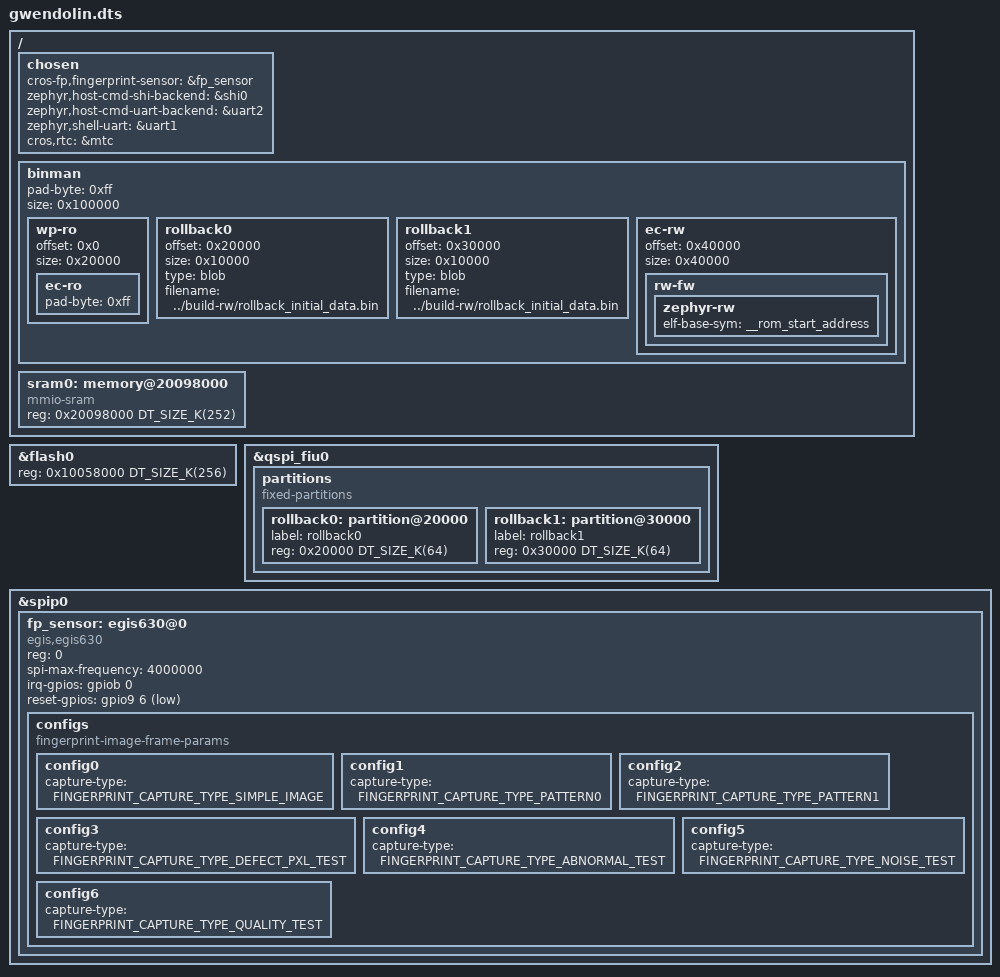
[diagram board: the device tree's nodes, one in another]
/* Copyright 2025 The ChromiumOS Authors.
 * Use of this source code is governed by a BSD-style license that can be
 * found in the LICENSE file.
 */

#include "gpio.dtsi"
#include "gwendolin/rwsig.dtsi"
#include "soc.dtsi"

#include <cros/integrated_fwid.dtsi>

#define EGIG630_DEFAULT_IMAGE_PROPS \
	width = <80>; \
	height = <64>; \
	bits-per-pixel = <8>; \
	frame-size = <5120>; \
	v4l2-pixel-format = "V4L2_PIX_FMT_GREY";

#define EGIG630_TEST_IMAGE_PROPS \
	width = <80>; \
	height = <64>; \
	bits-per-pixel = <16>; \
	frame-size = <10240>; \
	v4l2-pixel-format = "V4L2_PIX_FMT_GREY";

/ {
	chosen {
		cros-fp,fingerprint-sensor = &fp_sensor;
		zephyr,host-cmd-shi-backend = &shi0;
		zephyr,host-cmd-uart-backend = &uart2;
		zephyr,shell-uart = &uart1;
		cros,rtc = &mtc;
	};

	binman {
		pad-byte = <0xff>;

		/* Total Flash size is 1 MB. */
		size = <0x100000>;

		/* First 128 kB (uniform 4 kB sectors) used for RO */
		wp-ro {
			offset = <0x0>;
			size = <0x20000>;
			ec-ro {
				pad-byte = <0xff>;
			};
		};

		/* Two rollback sections (64 kB each) */
		rollback0 {
			offset = <0x20000>;
			size = <0x10000>;
			type = "blob";
			filename = "../build-rw/rollback_initial_data.bin";
		};

		rollback1 {
			offset = <0x30000>;
			size = <0x10000>;
			type = "blob";
			filename = "../build-rw/rollback_initial_data.bin";
		};

		/* 256 kB used for RW - gwendolin ECOS flash size */
		ec-rw {
			offset = <0x40000>;
			size = <0x40000>;
			rw-fw {
				/*
				 * Clang doesn't emit STT_SECTION symbols (also
				 * called 'section symbols'), so 'rom_start'
				 * symbol is not available. Fortunately, Zephyr
				 * linker scripts provide '__rom_start_address'
				 * symbol which points to the beginning of
				 * 'rom_start' section.
				 */
				zephyr-rw {
					elf-base-sym = "__rom_start_address";
				};
			};
		};
	};
};

/*
 *           ┌──────────────┐
 *           │   Reserved   │
 *           │     4KB      │
 *           ├──────────────┤0x200D7000
 *           │              │
 *           │              │
 *           │   Data RAM   │
 *           │     252KB    │
 *           │              │
 *           │              │
 * 0x10098000├──────────────┤0x20098000
 *           │              │
 *           │              │
 *           │              │
 *           │              │
 *           │   Code RAM   │
 *           │     256KB    │
 *           │              │
 *           │              │
 *           │              │
 *           │              │
 *           │              │
 * 0x10058000└──────────────┘
 */
&flash0 {
    reg = <0x10058000 DT_SIZE_K(256)>;
};

/delete-node/ &sram0;

/ {
	sram0: memory@20098000{
		compatible = "mmio-sram";
		reg = <0x20098000 DT_SIZE_K(252)>;
	};
};

&qspi_fiu0 {
	partitions {
		compatible = "fixed-partitions";
		#address-cells = <1>;
		#size-cells = <1>;

		/* First rollback section */
		rollback0: partition@20000 {
			label = "rollback0";
			reg = <0x20000 DT_SIZE_K(64)>;
		};

		/* Second rollback section */
		rollback1: partition@30000 {
			label = "rollback1";
			reg = <0x30000 DT_SIZE_K(64)>;
		};
	};
};

&spip0 {
	fp_sensor: egis630@0 {
		compatible = "egis,egis630";
		reg = <0>;
		spi-max-frequency = <4000000>;

		configs {
			compatible = "fingerprint-image-frame-params";
			config0 {
				EGIG630_DEFAULT_IMAGE_PROPS
				capture-type = "FINGERPRINT_CAPTURE_TYPE_SIMPLE_IMAGE";
			};
			config1 {
				EGIG630_TEST_IMAGE_PROPS
				capture-type = "FINGERPRINT_CAPTURE_TYPE_PATTERN0";
			};
			config2 {
				EGIG630_TEST_IMAGE_PROPS
				capture-type = "FINGERPRINT_CAPTURE_TYPE_PATTERN1";
			};
			config3 {
				EGIG630_TEST_IMAGE_PROPS
				capture-type = "FINGERPRINT_CAPTURE_TYPE_DEFECT_PXL_TEST";
			};
			config4 {
				EGIG630_TEST_IMAGE_PROPS
				capture-type = "FINGERPRINT_CAPTURE_TYPE_ABNORMAL_TEST";
			};
			config5 {
				EGIG630_TEST_IMAGE_PROPS
				capture-type = "FINGERPRINT_CAPTURE_TYPE_NOISE_TEST";
			};
			config6 {
				EGIG630_TEST_IMAGE_PROPS
				capture-type = "FINGERPRINT_CAPTURE_TYPE_QUALITY_TEST";
			};
		};

		irq-gpios = <&gpiob 0 GPIO_ACTIVE_HIGH>;
		reset-gpios = <&gpio9 6 GPIO_ACTIVE_LOW>;
	};
};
